# PIC32CM2532LS00064 register map
Vendor: Microchip Technology; Series: PIC32CMLS00; File version: 0
CPU: CM23 r0p0, selectable endian, MPU, no FPU, 2 interrupt priority bits, 71 interrupts
Registers are 32-bit, read-write, reset 0x0 unless marked. A register's access mark holds for its fields unless they carry their own. Offsets are from the block's base; [hi:lo] are bit positions; lines under a group give offsets from that group; {n}, {i} and the like mark numbered series; 'fields as' and 'values as' point back to an identical list.

## PM — Power Manager
Base 0x40000400
0x01 SLEEPCFG 8-bit reset 0x2 — Sleep Configuration
  [2:0] SLEEPMODE
    2=IDLE (CPU, AHBx, and APBx clocks are OFF); 4=STANDBY (ALL clocks are OFF, unless requested by sleepwalking peripheral); 6=OFF (All power domains are powered OFF)
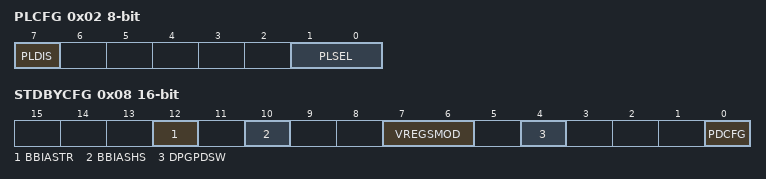
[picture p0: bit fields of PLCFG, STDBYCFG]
0x02 PLCFG 8-bit — Performance Level Configuration
  [7] PLDIS — Performance Level Disable
  [1:0] PLSEL — Performance Level Select
    0=PL0 (Performance Level 0); 2=PL2 (Performance Level 2)
0x03 PWCFG 8-bit — Power Configuration
  [1:0] RAMPSWC — RAM Power Switch Configuration
    0=SIZE0 (SRAM Retention: 64KB (512KB Flash), 32KB (256KB Flash), 16KB (128KB Flash)); 1=SIZE1 (SRAM Retention: 48KB (512KB Flash), 32KB (256KB Flash), 12KB (128KB Flash)); 2=SIZE2 (SRAM Retention: 32KB (512KB Flash), 32KB (256KB Flash), 8KB (128KB Flash)); 3=SIZE3 (SRAM Retention: 16KB (512KB Flash), 16KB (256KB Flash), 4KB (128KB Flash))
0x04 INTENCLR 8-bit — Interrupt Enable Clear
  [0] PLRDY — Performance Level Interrupt Enable
0x05 INTENSET 8-bit — Interrupt Enable Set
  [0] PLRDY — Performance Level Ready interrupt Enable
0x06 INTFLAG 8-bit — Interrupt Flag Status and Clear
  [0] PLRDY — Performance Level Ready
0x08 STDBYCFG 16-bit — Standby Configuration
  [12] BBIASTR — Back Bias for Trust RAM
  [10] BBIASHS — Back Bias for SRAM
  [7:6] VREGSMOD — Voltage Regulator Standby mode
    0=AUTO (Automatic mode); 1=PERFORMANCE (Performance oriented); 2=LP (Low Power oriented)
  [4] DPGPDSW — Dynamic Power Gating for PDSW
    0=DISABLED (Dynamic Power Gating disabled); 1=ENABLED (Dynamic Power Gating enabled)
  [0] PDCFG — Power Domain Configuration
    0=DEFAULT (PDSW power domain switching is handled by hardware.); 1=PDSW (PDSW is forced ACTIVE.)

## PORT — Port Module
Base 0x40003000
Same registers: PORT_SEC 0x40003200 (register names take the prefix PORT_SEC_), PORT_IOBUS 0x60000000 (register names take the prefix PORT_IOBUS_), PORT_IOBUS_SEC 0x60000200 (register names take the prefix PORT_IOBUS_SEC_)
{0x0+0x80*i} GROUP[{i}] (i=0..1) group
  0x00 DIR — Data Direction
    [31:0] DIR — Port Data Direction
  0x04 DIRCLR — Data Direction Clear
    [31:0] DIRCLR — Port Data Direction Clear
  0x08 DIRSET — Data Direction Set
    [31:0] DIRSET — Port Data Direction Set
  0x0C DIRTGL — Data Direction Toggle
    [31:0] DIRTGL — Port Data Direction Toggle
  0x10 OUT — Data Output Value
    [31:0] OUT — PORT Data Output Value
  0x14 OUTCLR — Data Output Value Clear
    [31:0] OUTCLR — PORT Data Output Value Clear
  0x18 OUTSET — Data Output Value Set
    [31:0] OUTSET — PORT Data Output Value Set
  0x1C OUTTGL — Data Output Value Toggle
    [31:0] OUTTGL — PORT Data Output Value Toggle
  0x20 IN ro — Data Input Value
    [31:0] IN — PORT Data Input Value
  0x24 CTRL — Control
    [31:0] SAMPLING — Input Sampling Mode
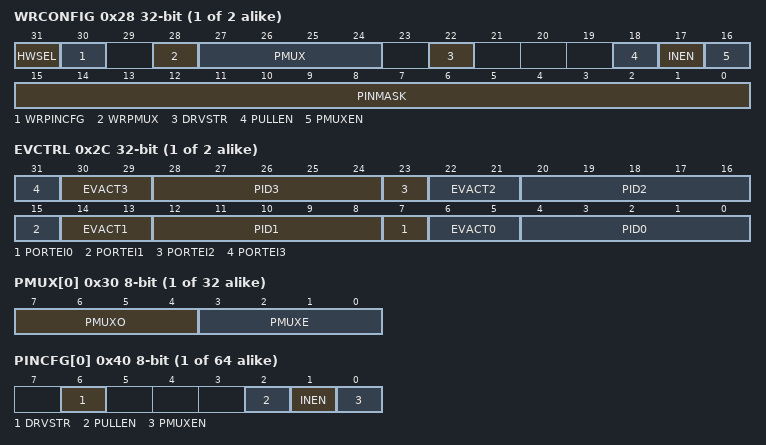
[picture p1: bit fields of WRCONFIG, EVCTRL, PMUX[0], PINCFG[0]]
  0x28 WRCONFIG wo — Write Configuration
    [31] HWSEL — Half-Word Select
    [30] WRPINCFG — Write PINCFG
    [28] WRPMUX — Write PMUX
    [27:24] PMUX — Peripheral Multiplexing
    [22] DRVSTR — Output Driver Strength Selection
    [18] PULLEN — Pull Enable
    [17] INEN — Input Enable
    [16] PMUXEN — Peripheral Multiplexer Enable
    [15:0] PINMASK — Pin Mask for Multiple Pin Configuration
  0x2C EVCTRL — Event Input Control
    [8n+7] PORTEI{n} (n=0..3) — PORT Event Input Enable {n}
    [30:29] EVACT3 — PORT Event Action 3
    [8n+4:8n] PID{n} (n=0..3) — PORT Event Pin Identifier {n}
    [22:21] EVACT2 — PORT Event Action 2
    [14:13] EVACT1 — PORT Event Action 1
    [6:5] EVACT0 — PORT Event Action 0
      0=OUT (Event output to pin); 1=SET (Set output register of pin on event); 2=CLR (Clear output register of pin on event); 3=TGL (Toggle output register of pin on event)
  {0x30+j} PMUX[{j}] (j=0..15) 8-bit — Peripheral Multiplexing
    [7:4] PMUXO — Peripheral Multiplexing for Odd-Numbered Pin
      0=A (Peripheral function A selected); 1=B (Peripheral function B selected); 2=C (Peripheral function C selected); 3=D (Peripheral function D selected); 4=E (Peripheral function E selected); 6=G (Peripheral function G selected); 7=H (Peripheral function H selected); 8=I (Peripheral function I selected); 9=J (Peripheral function J selected); 10=K (Peripheral function K selected)
    [3:0] PMUXE — Peripheral Multiplexing for Even-Numbered Pin
      values as PMUXO
  {0x40+j} PINCFG[{j}] (j=0..31) 8-bit — Pin Configuration
    [6] DRVSTR — Output Driver Strength Selection
    [2] PULLEN — Pull Enable
    [1] INEN — Input Enable
    [0] PMUXEN — Peripheral Multiplexer Enable
  0x60 INTENCLR — Interrupt Enable Clear
    [0] NSCHK — Non-Secure Check Interrupt Enable
  0x64 INTENSET — Interrupt Enable Set
    [0] NSCHK — Non-Secure Check Interrupt Enable
  0x68 INTFLAG — Interrupt Flag Status and Clear
    [0] NSCHK — Non-Secure Check
  0x6C NONSEC — Security Attribution
    [31:0] NONSEC — Port Security Attribution
  0x70 NSCHK — Security Attribution Check
    [31:0] NSCHK — Port Security Attribution Check
